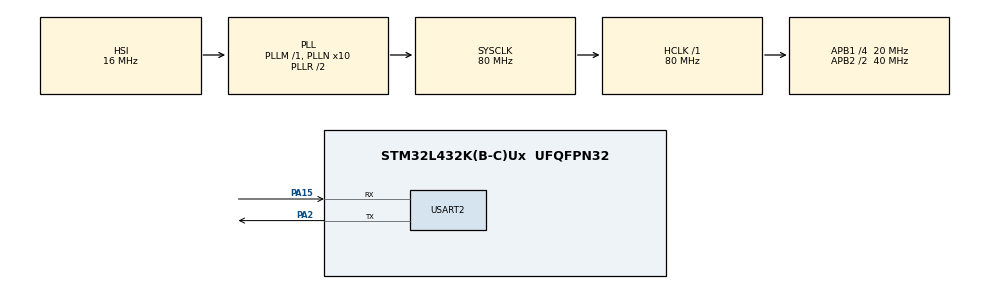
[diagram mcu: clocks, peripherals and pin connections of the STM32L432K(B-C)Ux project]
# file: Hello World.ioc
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Mcu.Family=STM32L4
Mcu.Name=STM32L432K(B-C)Ux
Mcu.Package=UFQFPN32
NVIC.PriorityGroup=NVIC_PRIORITYGROUP_4
NVIC.TIM1_BRK_TIM15_IRQn=true\:0\:0\:false\:false\:true\:true\:true
PA15\ (JTDI).Mode=Asynchronous
PA15\ (JTDI).Signal=USART2_RX
PA2.Mode=Asynchronous
PA2.Signal=USART2_TX
ProjectManager.HeapSize=0x200
ProjectManager.StackSize=0x400
ProjectManager.TargetToolchain=STM32CubeIDE
RCC.ADCFreq_Value=688000000
RCC.AHBFreq_Value=80000000
RCC.APB1CLKDivider=RCC_HCLK_DIV4
RCC.APB1Freq_Value=20000000
RCC.APB1TimFreq_Value=40000000
RCC.APB2CLKDivider=RCC_HCLK_DIV2
RCC.APB2Freq_Value=40000000
RCC.APB2TimFreq_Value=80000000
RCC.CortexFreq_Value=80000000
RCC.HCLKFreq_Value=80000000
RCC.HSE_VALUE=8000000
RCC.HSI48_VALUE=48000000
RCC.HSI_VALUE=16000000
RCC.LSE_VALUE=32768
RCC.MSI_VALUE=4000000
RCC.PLLN=10
RCC.PLLSAI1N=86
RCC.PLLSourceVirtual=RCC_PLLSOURCE_HSI
RCC.SYSCLKFreq_VALUE=80000000
RCC.SYSCLKSource=RCC_SYSCLKSOURCE_PLLCLK
RCC.USBFreq_Value=688000000
RCC.VCOOutputFreq_Value=160000000
TIM1.CounterMode=TIM_COUNTERMODE_CENTERALIGNED3
TIM1.Period=100-1
TIM1.Prescaler=80-1
TIM15.Period=100-1
TIM15.Prescaler=80-1
USART2.VirtualMode-Asynchronous=VM_ASYNC
VP_TIM15_VS_ClockSourceITR.Mode=TriggerSource_ITR0
VP_TIM1_VS_ClockSourceINT.Mode=Internal
VP_TIM1_VS_ClockSourceITR.Mode=TriggerSource_ITR0
board=custom

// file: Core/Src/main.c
/* USER CODE BEGIN Header */
/**
  ******************************************************************************
  * @file           : main.c
  * @brief          : Main program body
  ******************************************************************************
  * @attention
  *
  * <h2><center>&copy; Copyright (c) 2020 STMicroelectronics.
  * All rights reserved.</center></h2>
  *
  * This software component is licensed by ST under BSD 3-Clause license,
  * the "License"; You may not use this file except in compliance with the
  * License. You may obtain a copy of the License at:
  *                        opensource.org/licenses/BSD-3-Clause
  *
  ******************************************************************************
  */
/* USER CODE END Header */
#include "main.h"

TIM_HandleTypeDef htim1;
TIM_HandleTypeDef htim15;

UART_HandleTypeDef huart2;

void SystemClock_Config(void);
static void MX_GPIO_Init(void);
static void MX_TIM1_Init(void);
static void MX_TIM15_Init(void);
static void MX_USART2_UART_Init(void);

int main(void)
{
  /* USER CODE BEGIN 1 */
//	uint8_t MSG[31] = {'\0'};
//	  uint8_t X = 0;
  /* USER CODE END 1 */

  /* MCU Configuration--------------------------------------------------------*/

  /* Reset of all peripherals, Initializes the Flash interface and the Systick. */
  HAL_Init();

  /* Configure the system clock */
  SystemClock_Config();

  /* Initialize all configured peripherals */
  MX_GPIO_Init();
  MX_TIM1_Init();
  MX_TIM15_Init();
  MX_USART2_UART_Init();

  /* Infinite loop */
  /* USER CODE BEGIN WHILE */
  while (1)
  {
//	  sprintf(&MSG[0], "Hello Dudes! Tracing X = %d\r\n", X);
	       HAL_UART_Transmit(&huart2,(uint8_t *)"TEST", 6, HAL_MAX_DELAY);
	       HAL_Delay(500);
//	       X++;
    /* USER CODE END WHILE */

  }
}

void SystemClock_Config(void)
{
  RCC_OscInitTypeDef RCC_OscInitStruct = {0};
  RCC_ClkInitTypeDef RCC_ClkInitStruct = {0};
  RCC_PeriphCLKInitTypeDef PeriphClkInit = {0};

  /** Initializes the RCC Oscillators according to the specified parameters
  * in the RCC_OscInitTypeDef structure.
  */
  RCC_OscInitStruct.OscillatorType = RCC_OSCILLATORTYPE_HSI;
  RCC_OscInitStruct.HSIState = RCC_HSI_ON;
  RCC_OscInitStruct.HSICalibrationValue = RCC_HSICALIBRATION_DEFAULT;
  RCC_OscInitStruct.PLL.PLLState = RCC_PLL_ON;
  RCC_OscInitStruct.PLL.PLLSource = RCC_PLLSOURCE_HSI;
  RCC_OscInitStruct.PLL.PLLM = 1;
  RCC_OscInitStruct.PLL.PLLN = 10;
  RCC_OscInitStruct.PLL.PLLP = RCC_PLLP_DIV7;
  RCC_OscInitStruct.PLL.PLLQ = RCC_PLLQ_DIV2;
  RCC_OscInitStruct.PLL.PLLR = RCC_PLLR_DIV2;
  if (HAL_RCC_OscConfig(&RCC_OscInitStruct) != HAL_OK)
  {
    Error_Handler();
  }
  /** Initializes the CPU, AHB and APB buses clocks
  */
  RCC_ClkInitStruct.ClockType = RCC_CLOCKTYPE_HCLK|RCC_CLOCKTYPE_SYSCLK
                              |RCC_CLOCKTYPE_PCLK1|RCC_CLOCKTYPE_PCLK2;
  RCC_ClkInitStruct.SYSCLKSource = RCC_SYSCLKSOURCE_PLLCLK;
  RCC_ClkInitStruct.AHBCLKDivider = RCC_SYSCLK_DIV1;
  RCC_ClkInitStruct.APB1CLKDivider = RCC_HCLK_DIV4;
  RCC_ClkInitStruct.APB2CLKDivider = RCC_HCLK_DIV2;

  if (HAL_RCC_ClockConfig(&RCC_ClkInitStruct, FLASH_LATENCY_4) != HAL_OK)
  {
    Error_Handler();
  }
  PeriphClkInit.PeriphClockSelection = RCC_PERIPHCLK_USART2;
  PeriphClkInit.Usart2ClockSelection = RCC_USART2CLKSOURCE_PCLK1;
  if (HAL_RCCEx_PeriphCLKConfig(&PeriphClkInit) != HAL_OK)
  {
    Error_Handler();
  }
  /** Configure the main internal regulator output voltage
  */
  if (HAL_PWREx_ControlVoltageScaling(PWR_REGULATOR_VOLTAGE_SCALE1) != HAL_OK)
  {
    Error_Handler();
  }
}

static void MX_TIM1_Init(void)
{

  TIM_ClockConfigTypeDef sClockSourceConfig = {0};
  TIM_SlaveConfigTypeDef sSlaveConfig = {0};
  TIM_MasterConfigTypeDef sMasterConfig = {0};

  htim1.Instance = TIM1;
  htim1.Init.Prescaler = 80-1;
  htim1.Init.CounterMode = TIM_COUNTERMODE_CENTERALIGNED3;
  htim1.Init.Period = 100-1;
  htim1.Init.ClockDivision = TIM_CLOCKDIVISION_DIV1;
  htim1.Init.RepetitionCounter = 0;
  htim1.Init.AutoReloadPreload = TIM_AUTORELOAD_PRELOAD_DISABLE;
  if (HAL_TIM_Base_Init(&htim1) != HAL_OK)
  {
    Error_Handler();
  }
  sClockSourceConfig.ClockSource = TIM_CLOCKSOURCE_INTERNAL;
  if (HAL_TIM_ConfigClockSource(&htim1, &sClockSourceConfig) != HAL_OK)
  {
    Error_Handler();
  }
  sSlaveConfig.SlaveMode = TIM_SLAVEMODE_DISABLE;
  sSlaveConfig.InputTrigger = TIM_TS_ITR0;
  if (HAL_TIM_SlaveConfigSynchro(&htim1, &sSlaveConfig) != HAL_OK)
  {
    Error_Handler();
  }
  sMasterConfig.MasterOutputTrigger = TIM_TRGO_RESET;
  sMasterConfig.MasterOutputTrigger2 = TIM_TRGO2_RESET;
  sMasterConfig.MasterSlaveMode = TIM_MASTERSLAVEMODE_DISABLE;
  if (HAL_TIMEx_MasterConfigSynchronization(&htim1, &sMasterConfig) != HAL_OK)
  {
    Error_Handler();
  }

}

static void MX_TIM15_Init(void)
{

  TIM_SlaveConfigTypeDef sSlaveConfig = {0};
  TIM_MasterConfigTypeDef sMasterConfig = {0};

  htim15.Instance = TIM15;
  htim15.Init.Prescaler = 80-1;
  htim15.Init.CounterMode = TIM_COUNTERMODE_UP;
  htim15.Init.Period = 100-1;
  htim15.Init.ClockDivision = TIM_CLOCKDIVISION_DIV1;
  htim15.Init.RepetitionCounter = 0;
  htim15.Init.AutoReloadPreload = TIM_AUTORELOAD_PRELOAD_DISABLE;
  if (HAL_TIM_Base_Init(&htim15) != HAL_OK)
  {
    Error_Handler();
  }
  sSlaveConfig.SlaveMode = TIM_SLAVEMODE_DISABLE;
  sSlaveConfig.InputTrigger = TIM_TS_ITR0;
  if (HAL_TIM_SlaveConfigSynchro(&htim15, &sSlaveConfig) != HAL_OK)
  {
    Error_Handler();
  }
  sMasterConfig.MasterOutputTrigger = TIM_TRGO_RESET;
  sMasterConfig.MasterSlaveMode = TIM_MASTERSLAVEMODE_DISABLE;
  if (HAL_TIMEx_MasterConfigSynchronization(&htim15, &sMasterConfig) != HAL_OK)
  {
    Error_Handler();
  }

}

static void MX_USART2_UART_Init(void)
{

  huart2.Instance = USART2;
  huart2.Init.BaudRate = 115200;
  huart2.Init.WordLength = UART_WORDLENGTH_8B;
  huart2.Init.StopBits = UART_STOPBITS_1;
  huart2.Init.Parity = UART_PARITY_NONE;
  huart2.Init.Mode = UART_MODE_TX_RX;
  huart2.Init.HwFlowCtl = UART_HWCONTROL_NONE;
  huart2.Init.OverSampling = UART_OVERSAMPLING_16;
  huart2.Init.OneBitSampling = UART_ONE_BIT_SAMPLE_DISABLE;
  huart2.AdvancedInit.AdvFeatureInit = UART_ADVFEATURE_NO_INIT;
  if (HAL_UART_Init(&huart2) != HAL_OK)
  {
    Error_Handler();
  }

}

static void MX_GPIO_Init(void)
{

  /* GPIO Ports Clock Enable */
  __HAL_RCC_GPIOA_CLK_ENABLE();

}

void Error_Handler(void)
{
}

/************************ (C) COPYRIGHT STMicroelectronics *****END OF FILE****/
